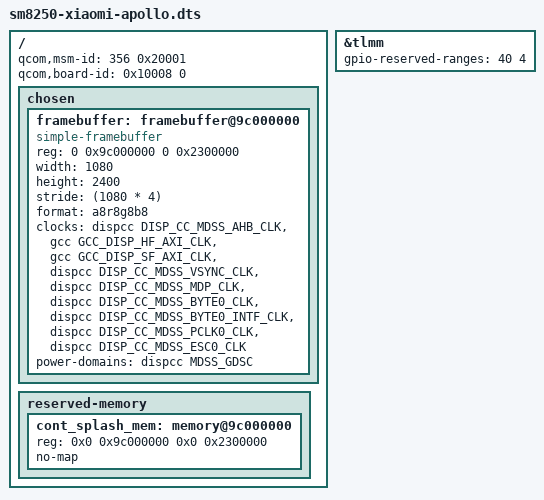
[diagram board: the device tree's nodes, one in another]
// SPDX-License-Identifier: BSD-3-Clause
/*
 */

#include <dt-bindings/regulator/qcom,rpmh-regulator.h>
#include "sm8250.dtsi"
#include "pm8150.dtsi"
#include "pm8150b.dtsi"
#include "pm8150l.dtsi"
#include "pm8009.dtsi"

/ {
	qcom,msm-id = <356 0x20001>; /* SM8250 v2.1 */
	qcom,board-id = <0x10008 0>;

	chosen {
		#address-cells = <2>;
		#size-cells = <2>;
		ranges;

		framebuffer: framebuffer@9c000000 {
			compatible = "simple-framebuffer";
			reg = <0 0x9c000000 0 0x2300000>;
			width = <1080>;
			height = <2400>;
			stride = <(1080 * 4)>;
			format = "a8r8g8b8";
			/*
			 * That's a lot of clocks, but it's necessary due
			 * to unused clk cleanup & no panel driver yet..
			 */
			clocks = <&dispcc DISP_CC_MDSS_AHB_CLK>,
				 <&gcc GCC_DISP_HF_AXI_CLK>,
				 <&gcc GCC_DISP_SF_AXI_CLK>,
				 <&dispcc DISP_CC_MDSS_VSYNC_CLK>,
				 <&dispcc DISP_CC_MDSS_MDP_CLK>,
				 <&dispcc DISP_CC_MDSS_BYTE0_CLK>,
				 <&dispcc DISP_CC_MDSS_BYTE0_INTF_CLK>,
				 <&dispcc DISP_CC_MDSS_PCLK0_CLK>,
				 <&dispcc DISP_CC_MDSS_ESC0_CLK>;
			power-domains = <&dispcc MDSS_GDSC>;
		};
	};

	reserved-memory {
		cont_splash_mem: memory@9c000000 {
			reg = <0x0 0x9c000000 0x0 0x2300000>;
			no-map;
		};
	};
};

&tlmm {
	gpio-reserved-ranges = <40 4>;
};
